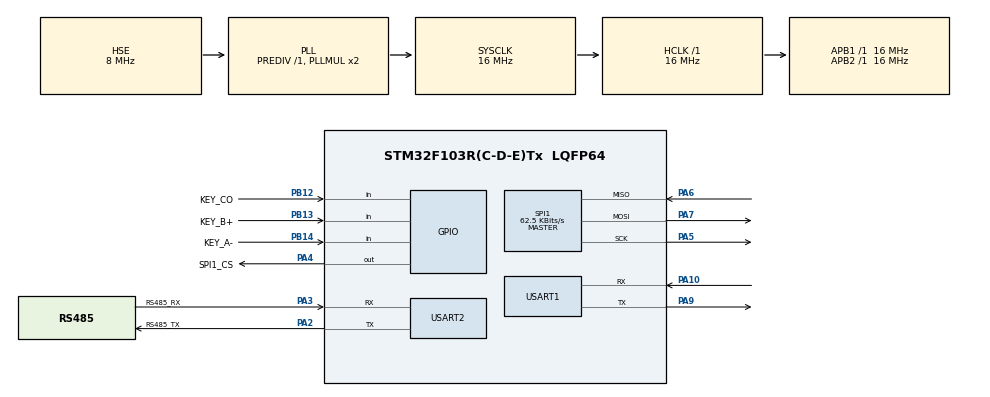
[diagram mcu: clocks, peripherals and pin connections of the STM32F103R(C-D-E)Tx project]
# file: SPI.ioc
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Dma.MEMTOMEM.4.Direction=DMA_MEMORY_TO_MEMORY
Dma.MEMTOMEM.4.Instance=DMA1_Channel1
Dma.MEMTOMEM.4.MemDataAlignment=DMA_MDATAALIGN_BYTE
Dma.MEMTOMEM.4.MemInc=DMA_MINC_ENABLE
Dma.MEMTOMEM.4.Mode=DMA_NORMAL
Dma.MEMTOMEM.4.PeriphDataAlignment=DMA_PDATAALIGN_BYTE
Dma.MEMTOMEM.4.PeriphInc=DMA_PINC_ENABLE
Dma.MEMTOMEM.4.Priority=DMA_PRIORITY_LOW
Dma.Request0=USART1_RX
Dma.Request1=USART1_TX
Dma.Request2=USART2_RX
Dma.Request3=USART2_TX
Dma.Request4=MEMTOMEM
Dma.Request5=SPI1_TX
Dma.Request6=SPI1_RX
Dma.SPI1_RX.6.Direction=DMA_PERIPH_TO_MEMORY
Dma.SPI1_RX.6.Instance=DMA1_Channel2
Dma.SPI1_RX.6.MemDataAlignment=DMA_MDATAALIGN_BYTE
Dma.SPI1_RX.6.MemInc=DMA_MINC_ENABLE
Dma.SPI1_RX.6.Mode=DMA_NORMAL
Dma.SPI1_RX.6.PeriphDataAlignment=DMA_PDATAALIGN_BYTE
Dma.SPI1_RX.6.PeriphInc=DMA_PINC_DISABLE
Dma.SPI1_RX.6.Priority=DMA_PRIORITY_LOW
Dma.SPI1_TX.5.Direction=DMA_MEMORY_TO_PERIPH
Dma.SPI1_TX.5.Instance=DMA1_Channel3
Dma.SPI1_TX.5.MemDataAlignment=DMA_MDATAALIGN_BYTE
Dma.SPI1_TX.5.MemInc=DMA_MINC_ENABLE
Dma.SPI1_TX.5.Mode=DMA_NORMAL
Dma.SPI1_TX.5.PeriphDataAlignment=DMA_PDATAALIGN_BYTE
Dma.SPI1_TX.5.PeriphInc=DMA_PINC_DISABLE
Dma.SPI1_TX.5.Priority=DMA_PRIORITY_LOW
Dma.USART1_RX.0.Direction=DMA_PERIPH_TO_MEMORY
Dma.USART1_RX.0.Instance=DMA1_Channel5
Dma.USART1_RX.0.MemDataAlignment=DMA_MDATAALIGN_BYTE
Dma.USART1_RX.0.MemInc=DMA_MINC_ENABLE
Dma.USART1_RX.0.Mode=DMA_NORMAL
Dma.USART1_RX.0.PeriphDataAlignment=DMA_PDATAALIGN_BYTE
Dma.USART1_RX.0.PeriphInc=DMA_PINC_DISABLE
Dma.USART1_RX.0.Priority=DMA_PRIORITY_LOW
Dma.USART1_TX.1.Direction=DMA_MEMORY_TO_PERIPH
Dma.USART1_TX.1.Instance=DMA1_Channel4
Dma.USART1_TX.1.MemDataAlignment=DMA_MDATAALIGN_BYTE
Dma.USART1_TX.1.MemInc=DMA_MINC_ENABLE
Dma.USART1_TX.1.Mode=DMA_NORMAL
Dma.USART1_TX.1.PeriphDataAlignment=DMA_PDATAALIGN_BYTE
Dma.USART1_TX.1.PeriphInc=DMA_PINC_DISABLE
Dma.USART1_TX.1.Priority=DMA_PRIORITY_LOW
Dma.USART2_RX.2.Direction=DMA_PERIPH_TO_MEMORY
Dma.USART2_RX.2.Instance=DMA1_Channel6
Dma.USART2_RX.2.MemDataAlignment=DMA_MDATAALIGN_BYTE
Dma.USART2_RX.2.MemInc=DMA_MINC_ENABLE
Dma.USART2_RX.2.Mode=DMA_NORMAL
Dma.USART2_RX.2.PeriphDataAlignment=DMA_PDATAALIGN_BYTE
Dma.USART2_RX.2.PeriphInc=DMA_PINC_DISABLE
Dma.USART2_RX.2.Priority=DMA_PRIORITY_LOW
Dma.USART2_TX.3.Direction=DMA_MEMORY_TO_PERIPH
Dma.USART2_TX.3.Instance=DMA1_Channel7
Dma.USART2_TX.3.MemDataAlignment=DMA_MDATAALIGN_BYTE
Dma.USART2_TX.3.MemInc=DMA_MINC_ENABLE
Dma.USART2_TX.3.Mode=DMA_NORMAL
Dma.USART2_TX.3.PeriphDataAlignment=DMA_PDATAALIGN_BYTE
Dma.USART2_TX.3.PeriphInc=DMA_PINC_DISABLE
Dma.USART2_TX.3.Priority=DMA_PRIORITY_LOW
FREERTOS.Events01=KEY_Event,Dynamic,NULL
FREERTOS.Tasks01=defaultTask,24,128,StartDefaultTask,Default,NULL,Dynamic,NULL,NULL;KEY_SCAN,8,128,key_scan,Default,NULL,Dynamic,NULL,NULL
Mcu.Family=STM32F1
Mcu.Name=STM32F103R(C-D-E)Tx
Mcu.Package=LQFP64
NVIC.DMA1_Channel2_IRQn=true\:5\:0\:false\:false\:true\:true\:false\:true\:true
NVIC.DMA1_Channel3_IRQn=true\:5\:0\:false\:false\:true\:true\:false\:true\:true
NVIC.DMA1_Channel4_IRQn=true\:5\:0\:false\:false\:true\:true\:false\:true\:true
NVIC.DMA1_Channel5_IRQn=true\:5\:0\:false\:false\:true\:true\:false\:true\:true
NVIC.DMA1_Channel6_IRQn=true\:5\:0\:false\:false\:true\:true\:false\:true\:true
NVIC.DMA1_Channel7_IRQn=true\:5\:0\:false\:false\:true\:true\:false\:true\:true
NVIC.PriorityGroup=NVIC_PRIORITYGROUP_4
NVIC.TIM6_IRQn=true\:15\:0\:false\:false\:true\:false\:false\:true\:true
NVIC.TimeBase=TIM6_IRQn
NVIC.TimeBaseIP=TIM6
NVIC.USART1_IRQn=true\:5\:0\:false\:false\:true\:true\:true\:true\:true
NVIC.USART2_IRQn=true\:5\:0\:false\:false\:true\:true\:true\:true\:true
PA10.Mode=Asynchronous
PA10.Signal=USART1_RX
PA13.Mode=Serial_Wire
PA13.Signal=SYS_JTMS-SWDIO
PA14.Mode=Serial_Wire
PA14.Signal=SYS_JTCK-SWCLK
PA2.GPIO_Label=RS485_TX
PA2.Mode=Asynchronous
PA2.Signal=USART2_TX
PA3.GPIO_Label=RS485_RX
PA3.Mode=Asynchronous
PA3.Signal=USART2_RX
PA4.GPIO_Label=SPI1_CS
PA4.Signal=GPIO_Output
PA5.Mode=Full_Duplex_Master
PA5.Signal=SPI1_SCK
PA6.Mode=Full_Duplex_Master
PA6.Signal=SPI1_MISO
PA7.Mode=Full_Duplex_Master
PA7.Signal=SPI1_MOSI
PA9.Mode=Asynchronous
PA9.Signal=USART1_TX
PB12.GPIO_Label=KEY_CO
PB12.Signal=GPIO_Input
PB13.GPIO_Label=KEY_B+
PB13.Signal=GPIO_Input
PB14.GPIO_Label=KEY_A-
PB14.Signal=GPIO_Input
PD0-OSC_IN.Mode=HSE-External-Oscillator
PD0-OSC_IN.Signal=RCC_OSC_IN
PD1-OSC_OUT.Mode=HSE-External-Oscillator
PD1-OSC_OUT.Signal=RCC_OSC_OUT
ProjectManager.HeapSize=0x200
ProjectManager.StackSize=0x400
ProjectManager.TargetToolchain=MDK-ARM V5.32
RCC.AHBFreq_Value=16000000
RCC.APB1Freq_Value=16000000
RCC.APB1TimFreq_Value=16000000
RCC.APB2Freq_Value=16000000
RCC.APB2TimFreq_Value=16000000
RCC.HCLKFreq_Value=16000000
RCC.PLLSourceVirtual=RCC_PLLSOURCE_HSE
RCC.SYSCLKFreq_VALUE=16000000
RCC.SYSCLKSource=RCC_SYSCLKSOURCE_PLLCLK
RCC.USBFreq_Value=16000000
SPI1.BaudRatePrescaler=SPI_BAUDRATEPRESCALER_256
SPI1.CLKPhase=SPI_PHASE_2EDGE
SPI1.CLKPolarity=SPI_POLARITY_HIGH
SPI1.CalculateBaudRate=62.5 KBits/s
SPI1.Direction=SPI_DIRECTION_2LINES
SPI1.Mode=SPI_MODE_MASTER
SPI1.VirtualType=VM_MASTER
USART1.VirtualMode=VM_ASYNC
USART2.VirtualMode=VM_ASYNC
VP_FREERTOS_VS_CMSIS_V2.Mode=CMSIS_V2
VP_SYS_VS_tim6.Mode=TIM6
board=custom

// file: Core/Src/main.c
/* USER CODE BEGIN Header */
/**
  ******************************************************************************
  * @file           : main.c
  * @brief          : Main program body
  ******************************************************************************
  * @attention
  *
  * Copyright (c) 2024 STMicroelectronics.
  * All rights reserved.
  *
  * This software is licensed under terms that can be found in the LICENSE file
  * in the root directory of this software component.
  * If no LICENSE file comes with this software, it is provided AS-IS.
  *
  ******************************************************************************
  */
/* USER CODE END Header */
#include "main.h"
#include "cmsis_os.h"
#include "dma.h"
#include "spi.h"
#include "usart.h"
#include "gpio.h"

/* USER CODE BEGIN Includes */
#include "key.h"
#include "lcd.h"
#include "lcd_init.h"
/* USER CODE END Includes */

void SystemClock_Config(void);
void MX_FREERTOS_Init(void);

int main(void)
{

  /* MCU Configuration--------------------------------------------------------*/

  /* Reset of all peripherals, Initializes the Flash interface and the Systick. */
  HAL_Init();

  /* Configure the system clock */
  SystemClock_Config();

  /* Initialize all configured peripherals */
  MX_GPIO_Init();
  MX_DMA_Init();
  MX_SPI1_Init();
  MX_USART2_UART_Init();
  MX_USART1_UART_Init();
  /* USER CODE BEGIN 2 */
  KEY_Init();
	LCD_Init();
	LCD_Fill(0,0,LCD_W,LCD_H,WHITE);
  /* USER CODE END 2 */

  /* Init scheduler */
  osKernelInitialize();

  /* Call init function for freertos objects (in cmsis_os2.c) */
  MX_FREERTOS_Init();

  /* Start scheduler */
  osKernelStart();

  /* We should never get here as control is now taken by the scheduler */

  /* Infinite loop */
  while (1)
  {

  }
}

void SystemClock_Config(void)
{
  RCC_OscInitTypeDef RCC_OscInitStruct = {0};
  RCC_ClkInitTypeDef RCC_ClkInitStruct = {0};

  /** Initializes the RCC Oscillators according to the specified parameters
  * in the RCC_OscInitTypeDef structure.
  */
  RCC_OscInitStruct.OscillatorType = RCC_OSCILLATORTYPE_HSE;
  RCC_OscInitStruct.HSEState = RCC_HSE_ON;
  RCC_OscInitStruct.HSEPredivValue = RCC_HSE_PREDIV_DIV1;
  RCC_OscInitStruct.HSIState = RCC_HSI_ON;
  RCC_OscInitStruct.PLL.PLLState = RCC_PLL_ON;
  RCC_OscInitStruct.PLL.PLLSource = RCC_PLLSOURCE_HSE;
  RCC_OscInitStruct.PLL.PLLMUL = RCC_PLL_MUL2;
  if (HAL_RCC_OscConfig(&RCC_OscInitStruct) != HAL_OK)
  {
    Error_Handler();
  }

  /** Initializes the CPU, AHB and APB buses clocks
  */
  RCC_ClkInitStruct.ClockType = RCC_CLOCKTYPE_HCLK|RCC_CLOCKTYPE_SYSCLK
                              |RCC_CLOCKTYPE_PCLK1|RCC_CLOCKTYPE_PCLK2;
  RCC_ClkInitStruct.SYSCLKSource = RCC_SYSCLKSOURCE_PLLCLK;
  RCC_ClkInitStruct.AHBCLKDivider = RCC_SYSCLK_DIV1;
  RCC_ClkInitStruct.APB1CLKDivider = RCC_HCLK_DIV1;
  RCC_ClkInitStruct.APB2CLKDivider = RCC_HCLK_DIV1;

  if (HAL_RCC_ClockConfig(&RCC_ClkInitStruct, FLASH_LATENCY_0) != HAL_OK)
  {
    Error_Handler();
  }
}

void HAL_TIM_PeriodElapsedCallback(TIM_HandleTypeDef *htim)
{
  if (htim->Instance == TIM6) {
    HAL_IncTick();
  }
}

void Error_Handler(void)
{
  __disable_irq();
  while (1)
  {
  }
}

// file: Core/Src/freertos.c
/* USER CODE BEGIN Header */
/**
  ******************************************************************************
  * File Name          : freertos.c
  * Description        : Code for freertos applications
  ******************************************************************************
  * @attention
  *
  * Copyright (c) 2024 STMicroelectronics.
  * All rights reserved.
  *
  * This software is licensed under terms that can be found in the LICENSE file
  * in the root directory of this software component.
  * If no LICENSE file comes with this software, it is provided AS-IS.
  *
  ******************************************************************************
  */
/* USER CODE END Header */

#include "FreeRTOS.h"
#include "task.h"
#include "main.h"
#include "cmsis_os.h"

/* USER CODE BEGIN Includes */
#include "task_key.h"
#include "log2usart.h"
#include "spi.h"
#include "lcd_init.h"
/* USER CODE END Includes */

/* Definitions for defaultTask */
osThreadId_t defaultTaskHandle;
const osThreadAttr_t defaultTask_attributes = {
  .name = "defaultTask",
  .stack_size = 128 * 4,
  .priority = (osPriority_t) osPriorityNormal,
};
/* Definitions for KEY_SCAN */
osThreadId_t KEY_SCANHandle;
const osThreadAttr_t KEY_SCAN_attributes = {
  .name = "KEY_SCAN",
  .stack_size = 128 * 4,
  .priority = (osPriority_t) osPriorityLow,
};
/* Definitions for KEY_Event */
osEventFlagsId_t KEY_EventHandle;
const osEventFlagsAttr_t KEY_Event_attributes = {
  .name = "KEY_Event"
};

void StartDefaultTask(void *argument);
void key_scan(void *argument);

void MX_FREERTOS_Init(void); /* (MISRA C 2004 rule 8.1) */

void MX_FREERTOS_Init(void) {

  /* Create the thread(s) */
  /* creation of defaultTask */
  defaultTaskHandle = osThreadNew(StartDefaultTask, NULL, &defaultTask_attributes);

  /* creation of KEY_SCAN */
  KEY_SCANHandle = osThreadNew(key_scan, NULL, &KEY_SCAN_attributes);

  /* Create the event(s) */
  /* creation of KEY_Event */
  KEY_EventHandle = osEventFlagsNew(&KEY_Event_attributes);

}

void StartDefaultTask(void *argument)
{
  for(;;)
  {
    osDelay(1);
  }
}

void key_scan(void *argument)
{
  /* USER CODE BEGIN key_scan */
  /* Infinite loop */
  for(;;)
  {
    osDelay(500);
  }
  /* USER CODE END key_scan */
}
